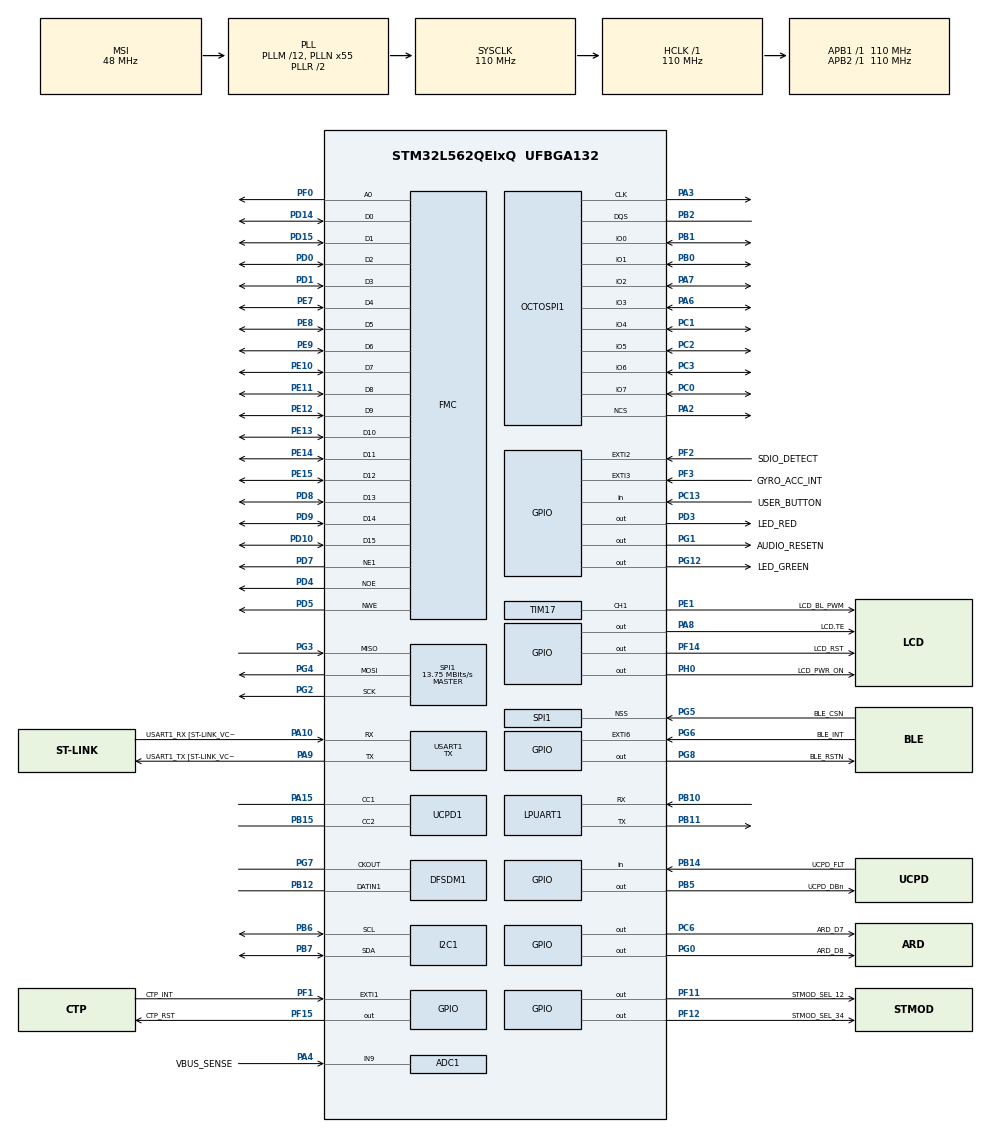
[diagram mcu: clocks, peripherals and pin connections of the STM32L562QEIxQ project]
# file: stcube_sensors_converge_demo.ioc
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ADC1.Channel-0\#ChannelRegularConversion=ADC_CHANNEL_9
ADC1.ClockPrescaler=ADC_CLOCK_ASYNC_DIV12
ADC1.NbrOfConversionFlag=1
ADC1.OffsetNumber-0\#ChannelRegularConversion=ADC_OFFSET_NONE
ADC1.Rank-0\#ChannelRegularConversion=1
ADC1.SamplingTime-0\#ChannelRegularConversion=ADC_SAMPLETIME_2CYCLES_5
ADC1.master=1
FREERTOS.Queues01=queue_serial,16,serial_task_request_t,0,Dynamic,NULL,NULL;queue_i2c_request,16,i2c_bus_task_request_t,0,Dynamic,NULL,NULL;queue_sample_logging_request,16,sample_logging_task_request_t,0,Dynamic,NULL,NULL
FREERTOS.Tasks01=idle,8,1024,StartIdleTask,Default,NULL,Dynamic,NULL,NULL;serial,9,1024,StartSerialTask,Default,NULL,Dynamic,NULL,NULL;i2c_bus,11,1024,StartI2cBusTask,Default,NULL,Dynamic,NULL,NULL;button,11,512,StartButtonTask,Default,NULL,Dynamic,NULL,NULL;display,12,1024,StartDisplayTask,Default,NULL,Dynamic,NULL,NULL;motion,12,1024,StartMotionTask,Default,NULL,Dynamic,NULL,NULL;adc,12,1024,StartAdcTask,Default,NULL,Dynamic,NULL,NULL;sample_logging,10,1024,StartSampleLoggingTask,Default,NULL,Dynamic,NULL,NULL
FREERTOS.configENABLE_FPU=1
FREERTOS.configTOTAL_HEAP_SIZE=40000
FREERTOS.configUSE_NEWLIB_REENTRANT=1
I2C1.Timing=0x40505681
Mcu.Family=STM32L5
Mcu.Name=STM32L562QEIxQ
Mcu.Package=UFBGA132
Mcu.TrustZone=disable
NVIC.ADC1_2_IRQn=true\:5\:0\:false\:false\:true\:true\:true\:true
NVIC.I2C1_ER_IRQn=true\:5\:0\:false\:false\:true\:true\:true\:true
NVIC.I2C1_EV_IRQn=true\:5\:0\:false\:false\:true\:true\:true\:true
NVIC.PriorityGroup=NVIC_PRIORITYGROUP_3
NVIC.TIM15_IRQn=true\:0\:0\:true\:false\:true\:false\:false\:true
NVIC.TimeBase=TIM15_IRQn
NVIC.TimeBaseIP=TIM15
NVIC.USART1_IRQn=true\:5\:0\:false\:false\:true\:true\:true\:true
PA10.GPIO_Label=USART1_RX [ST-LINK_VCP_TX]
PA10.Mode=Asynchronous
PA10.Signal=USART1_RX
PA11.Signal=USB_DM
PA12.Signal=USB_DP
PA13\ (JTMS/SWDIO).Mode=Trace_Asynchronous_SW
PA13\ (JTMS/SWDIO).Signal=DEBUG_JTMS-SWDIO
PA14\ (JTCK/SWCLK).Mode=Trace_Asynchronous_SW
PA14\ (JTCK/SWCLK).Signal=DEBUG_JTCK-SWCLK
PA15\ (JTDI).Mode=Source_AllSignals
PA15\ (JTDI).Signal=UCPD1_CC1
PA2.Mode=octods_mode
PA2.Signal=OCTOSPI1_NCS
PA3.Mode=octods_mode
PA3.Signal=OCTOSPI1_CLK
PA4.GPIO_Label=VBUS_SENSE
PA4.Signal=ADCx_IN9
PA6.Mode=octods_mode
PA6.Signal=OCTOSPI1_IO3
PA7.Mode=octods_mode
PA7.Signal=OCTOSPI1_IO2
PA8.GPIO_Label=LCD.TE
PA8.Signal=GPIO_Output
PA9.GPIO_Label=USART1_TX [ST-LINK_VCP_RX]
PA9.Mode=Asynchronous
PA9.Signal=USART1_TX
PB0.Mode=octods_mode
PB0.Signal=OCTOSPI1_IO1
PB1.Mode=octods_mode
PB1.Signal=OCTOSPI1_IO0
PB10.Mode=Asynchronous
PB10.Signal=LPUART1_RX
PB11.Mode=Asynchronous
PB11.Signal=LPUART1_TX
PB12.Signal=S_DATAIN1DFSDM1
PB14.GPIO_Label=UCPD_FLT
PB14.Signal=GPIO_Input
PB15.Mode=Source_AllSignals
PB15.Signal=UCPD1_CC2
PB2.Mode=octods_mode
PB2.Signal=OCTOSPI1_DQS
PB3\ (JTDO/TRACESWO).Mode=Trace_Asynchronous_SW
PB3\ (JTDO/TRACESWO).Signal=DEBUG_JTDO-SWO
PB5.GPIO_Label=UCPD_DBn
PB5.Signal=GPIO_Output
PB6.GPIO_Pu=GPIO_PULLUP
PB6.Mode=I2C
PB6.Signal=I2C1_SCL
PB7.GPIO_Pu=GPIO_PULLUP
PB7.Mode=I2C
PB7.Signal=I2C1_SDA
PC0.Mode=octods_mode
PC0.Signal=OCTOSPI1_IO7
PC1.Mode=octods_mode
PC1.Signal=OCTOSPI1_IO4
PC10.Signal=SDMMC1_D2
PC11.Signal=SDMMC1_D3
PC12.Signal=SDMMC1_CK
PC13.GPIO_Label=USER_BUTTON
PC13.Signal=GPIO_Input
PC14-OSC32_IN\ (PC14).Mode=LSE-External-Oscillator
PC14-OSC32_IN\ (PC14).Signal=RCC_OSC32_IN
PC15-OSC32_OUT\ (PC15).Mode=LSE-External-Oscillator
PC15-OSC32_OUT\ (PC15).Signal=RCC_OSC32_OUT
PC2.Mode=octods_mode
PC2.Signal=OCTOSPI1_IO5
PC3.Mode=octods_mode
PC3.Signal=OCTOSPI1_IO6
PC6.GPIO_Label=ARD_D7
PC6.Signal=GPIO_Output
PC8.Signal=SDMMC1_D0
PC9.Signal=SDMMC1_D1
PD0.Signal=FMC_D2_DA2
PD1.Signal=FMC_D3_DA3
PD10.Signal=FMC_D15_DA15
PD14.Signal=FMC_D0_DA0
PD15.Signal=FMC_D1_DA1
PD2.Signal=SDMMC1_CMD
PD3.GPIO_Label=LED_RED
PD3.PinState=GPIO_PIN_SET
PD3.Signal=GPIO_Output
PD4.Signal=FMC_NOE
PD5.Signal=FMC_NWE
PD7.Mode=NorPsramChipSelect1_1
PD7.Signal=FMC_NE1
PD8.Signal=FMC_D13_DA13
PD9.Signal=FMC_D14_DA14
PE1.GPIO_Label=LCD_BL_PWM
PE1.Signal=S_TIM17_CH1
PE10.Signal=FMC_D7_DA7
PE11.Signal=FMC_D8_DA8
PE12.Signal=FMC_D9_DA9
PE13.Signal=FMC_D10_DA10
PE14.Signal=FMC_D11_DA11
PE15.Signal=FMC_D12_DA12
PE2.Signal=SAI1_MCLK_A
PE3.Signal=SAI1_SD_B
PE4.Signal=SAI1_FS_A
PE5.Signal=SAI1_SCK_A
PE6.Signal=SAI1_SD_A
PE7.Signal=FMC_D4_DA4
PE8.Signal=FMC_D5_DA5
PE9.Signal=FMC_D6_DA6
PF0.Signal=FMC_A0
PF1.GPIO_Label=CTP_INT
PF1.Signal=GPXTI1
PF11.GPIO_Label=STMOD_SEL_12
PF11.Signal=GPIO_Output
PF12.GPIO_Label=STMOD_SEL_34
PF12.Signal=GPIO_Output
PF14.GPIO_Label=LCD_RST
PF14.Signal=GPIO_Output
PF15.GPIO_Label=CTP_RST
PF15.Signal=GPIO_Output
PF2.GPIO_Label=SDIO_DETECT
PF2.Signal=GPXTI2
PF3.GPIO_Label=GYRO_ACC_INT
PF3.Signal=GPXTI3
PG0.GPIO_Label=ARD_D8
PG0.Signal=GPIO_Output
PG1.GPIO_Label=AUDIO_RESETN
PG1.Signal=GPIO_Output
PG12.GPIO_Label=LED_GREEN
PG12.Signal=GPIO_Output
PG2.Mode=Full_Duplex_Master
PG2.Signal=SPI1_SCK
PG3.Mode=Full_Duplex_Master
PG3.Signal=SPI1_MISO
PG4.Mode=Full_Duplex_Master
PG4.Signal=SPI1_MOSI
PG5.GPIO_Label=BLE_CSN
PG5.Mode=NSS_Signal_Hard_Input
PG5.Signal=SPI1_NSS
PG6.GPIO_Label=BLE_INT
PG6.Signal=GPXTI6
PG7.Signal=S_CKOUTDFSDM1
PG8.GPIO_Label=BLE_RSTN
PG8.Signal=GPIO_Output
PH0-OSC_IN\ (PH0).GPIO_Label=LCD_PWR_ON
PH0-OSC_IN\ (PH0).GPIO_ModeDefaultOutputPP=GPIO_MODE_OUTPUT_PP
PH0-OSC_IN\ (PH0).PinState=GPIO_PIN_RESET
PH0-OSC_IN\ (PH0).Signal=GPIO_Output
ProjectManager.HeapSize=0x200
ProjectManager.StackSize=0x400
ProjectManager.TargetToolchain=STM32CubeIDE
RCC.ADCFreq_Value=96000000
RCC.AHBFreq_Value=110000000
RCC.APB1Freq_Value=110000000
RCC.APB1TimFreq_Value=110000000
RCC.APB2Freq_Value=110000000
RCC.APB2TimFreq_Value=110000000
RCC.CK48CLockSelection=RCC_USBCLKSOURCE_MSI
RCC.CortexFreq_Value=110000000
RCC.HCLKFreq_Value=110000000
RCC.HSE_VALUE=8000000
RCC.HSI48_VALUE=48000000
RCC.HSI_VALUE=16000000
RCC.MSIClockRange=RCC_MSIRANGE_11
RCC.MSI_VALUE=48000000
RCC.PLLM=12
RCC.PLLN=55
RCC.PLLSAI1M=4
RCC.PLLSAI1N=48
RCC.PLLSAI1P=RCC_PLLP_DIV17
RCC.PLLSAI1Source=RCC_PLLSAI1SOURCE_HSI
RCC.SDMMCClockSelection=RCC_SDIOCLKSOURCE_CLK48
RCC.SYSCLKFreq_VALUE=110000000
RCC.SYSCLKSource=RCC_SYSCLKSOURCE_PLLCLK
RCC.USBFreq_Value=48000000
RCC.VCOOutputFreq_Value=220000000
SH.ADCx_IN9.0=ADC1_IN9,IN9-Single-Ended
SH.FMC_A0.0=FMC_A0,A0_1
SH.FMC_D0_DA0.0=FMC_DA0
SH.FMC_D0_DA0.1=FMC_D0,16b-d1
SH.FMC_D10_DA10.0=FMC_DA10
SH.FMC_D10_DA10.1=FMC_D10,16b-d1
SH.FMC_D11_DA11.0=FMC_DA11
SH.FMC_D11_DA11.1=FMC_D11,16b-d1
SH.FMC_D12_DA12.0=FMC_DA12
SH.FMC_D12_DA12.1=FMC_D12,16b-d1
SH.FMC_D13_DA13.0=FMC_DA13
SH.FMC_D13_DA13.1=FMC_D13,16b-d1
SH.FMC_D14_DA14.0=FMC_DA14
SH.FMC_D14_DA14.1=FMC_D14,16b-d1
SH.FMC_D15_DA15.0=FMC_DA15
SH.FMC_D15_DA15.1=FMC_D15,16b-d1
SH.FMC_D1_DA1.0=FMC_DA1
SH.FMC_D1_DA1.1=FMC_D1,16b-d1
SH.FMC_D2_DA2.0=FMC_DA2
SH.FMC_D2_DA2.1=FMC_D2,16b-d1
SH.FMC_D3_DA3.0=FMC_DA3
SH.FMC_D3_DA3.1=FMC_D3,16b-d1
SH.FMC_D4_DA4.0=FMC_DA4
SH.FMC_D4_DA4.1=FMC_D4,16b-d1
SH.FMC_D5_DA5.0=FMC_DA5
SH.FMC_D5_DA5.1=FMC_D5,16b-d1
SH.FMC_D6_DA6.0=FMC_DA6
SH.FMC_D6_DA6.1=FMC_D6,16b-d1
SH.FMC_D7_DA7.0=FMC_DA7
SH.FMC_D7_DA7.1=FMC_D7,16b-d1
SH.FMC_D8_DA8.0=FMC_DA8
SH.FMC_D8_DA8.1=FMC_D8,16b-d1
SH.FMC_D9_DA9.0=FMC_DA9
SH.FMC_D9_DA9.1=FMC_D9,16b-d1
SH.FMC_NOE.0=FMC_NOE,Lcd1
SH.FMC_NWE.0=FMC_NWE,Lcd1
SH.S_CKOUTDFSDM1.0=DFSDM1_CKOUT,CKOUT
SH.S_DATAIN1DFSDM1.0=DFSDM1_DATIN1,Manchester_input_from_ch1
SH.S_TIM17_CH1.0=TIM17_CH1,PWM Generation1 CH1
SPI1.BaudRatePrescaler=SPI_BAUDRATEPRESCALER_8
SPI1.CalculateBaudRate=13.75 MBits/s
SPI1.Direction=SPI_DIRECTION_2LINES
SPI1.Mode=SPI_MODE_MASTER
SPI1.VirtualNSS=VM_NSSHARD
SPI1.VirtualType=VM_MASTER
TIM17.Channel=TIM_CHANNEL_1
USART1.DMADisableonRxErrorParam=ADVFEATURE_DMA_DISABLEONRXERROR
USART1.FIFOMode=FIFOMODE_ENABLE
USART1.Mode=MODE_TX
USART1.OverrunDisableParam=ADVFEATURE_OVERRUN_DISABLE
USART1.RxPinLevelInvertParam=ADVFEATURE_RXINV_DISABLE
USART1.TXFIFOThreshold=TXFIFO_THRESHOLD_1EIGHTHFULL
USART1.VirtualMode-Asynchronous=VM_ASYNC
VP_ADC1_TempSens_Input.Mode=IN-TempSens
VP_DFSDM1_VS_IN0.Mode=Parallel_Input_ch0
VP_DFSDM1_VS_IN2.Mode=Parallel_Input_ch2
VP_FREERTOS_VS_CMSIS_V2.Mode=CMSIS_V2
VP_PWR_VS_DBSignals.Mode=DisableDeadBatterySignals
VP_PWR_VS_SECSignals.Mode=Security/Privilege
VP_SYS_VS_tim15.Mode=TIM15
VP_TIM16_VS_ClockSourceINT.Mode=Enable_Timer
VP_TIM17_VS_ClockSourceINT.Mode=Enable_Timer
VP_TIM4_VS_ClockSourceITR.Mode=TriggerSource_ITR1
VP_TIM4_VS_ControllerModeClock.Mode=Clock Mode
board=STM32L562E-DK

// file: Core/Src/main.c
/* USER CODE BEGIN Header */
/**
  ******************************************************************************
  * @file           : main.c
  * @brief          : Main program body
  ******************************************************************************
  * @attention
  *
  * <h2><center>&copy; Copyright (c) 2021 STMicroelectronics.
  * All rights reserved.</center></h2>
  *
  * This software component is licensed by ST under BSD 3-Clause license,
  * the "License"; You may not use this file except in compliance with the
  * License. You may obtain a copy of the License at:
  *                        opensource.org/licenses/BSD-3-Clause
  *
  ******************************************************************************
  */
/* USER CODE END Header */
#include "main.h"
#include "cmsis_os.h"
#include "adc.h"
#include "dfsdm.h"
#include "i2c.h"
#include "usart.h"
#include "octospi.h"
#include "spi.h"
#include "tim.h"
#include "ucpd.h"
#include "gpio.h"
#include "fmc.h"

/* USER CODE BEGIN Includes */

#include "application.h"

/* USER CODE END Includes */

void SystemClock_Config(void);
void MX_FREERTOS_Init(void);

int main(void)
{
  /* USER CODE BEGIN 1 */

  application_on_reset();

  /* USER CODE END 1 */

  /* MCU Configuration--------------------------------------------------------*/

  /* Reset of all peripherals, Initializes the Flash interface and the Systick. */
  HAL_Init();

  /* Configure the system clock */
  SystemClock_Config();

  /* Initialize all configured peripherals */
  MX_GPIO_Init();
  MX_ADC1_Init();
  MX_DFSDM1_Init();
  MX_FMC_Init();
  MX_I2C1_Init();
  MX_LPUART1_UART_Init();
  MX_USART1_UART_Init();
  MX_OCTOSPI1_Init();
  MX_SPI1_Init();
  MX_TIM4_Init();
  MX_TIM16_Init();
  MX_TIM17_Init();
  MX_UCPD1_Init();
  /* USER CODE BEGIN 2 */

  application_init();

  __enable_irq();
  /* USER CODE END 2 */

  /* Init scheduler */
  osKernelInitialize();  /* Call init function for freertos objects (in freertos.c) */
  MX_FREERTOS_Init();
  /* Start scheduler */
  osKernelStart();

  /* We should never get here as control is now taken by the scheduler */
  /* Infinite loop */
  __disable_irq();
  while (1)
  {

    /* USER CODE BEGIN 3 */
    HAL_GPIO_WritePin(LED_RED_GPIO_Port, LED_RED_Pin, GPIO_PIN_RESET);

    application_end_of_main();
  }
  /* USER CODE END 3 */
}

void SystemClock_Config(void)
{
  RCC_OscInitTypeDef RCC_OscInitStruct = {0};
  RCC_ClkInitTypeDef RCC_ClkInitStruct = {0};

  /** Configure the main internal regulator output voltage
  */
  if (HAL_PWREx_ControlVoltageScaling(PWR_REGULATOR_VOLTAGE_SCALE0) != HAL_OK)
  {
    Error_Handler();
  }
  /** Initializes the RCC Oscillators according to the specified parameters
  * in the RCC_OscInitTypeDef structure.
  */
  RCC_OscInitStruct.OscillatorType = RCC_OSCILLATORTYPE_HSI|RCC_OSCILLATORTYPE_MSI;
  RCC_OscInitStruct.HSIState = RCC_HSI_ON;
  RCC_OscInitStruct.HSICalibrationValue = RCC_HSICALIBRATION_DEFAULT;
  RCC_OscInitStruct.MSIState = RCC_MSI_ON;
  RCC_OscInitStruct.MSICalibrationValue = RCC_MSICALIBRATION_DEFAULT;
  RCC_OscInitStruct.MSIClockRange = RCC_MSIRANGE_11;
  RCC_OscInitStruct.PLL.PLLState = RCC_PLL_ON;
  RCC_OscInitStruct.PLL.PLLSource = RCC_PLLSOURCE_MSI;
  RCC_OscInitStruct.PLL.PLLM = 12;
  RCC_OscInitStruct.PLL.PLLN = 55;
  RCC_OscInitStruct.PLL.PLLP = RCC_PLLP_DIV7;
  RCC_OscInitStruct.PLL.PLLQ = RCC_PLLQ_DIV2;
  RCC_OscInitStruct.PLL.PLLR = RCC_PLLR_DIV2;
  if (HAL_RCC_OscConfig(&RCC_OscInitStruct) != HAL_OK)
  {
    Error_Handler();
  }
  /** Initializes the CPU, AHB and APB buses clocks
  */
  RCC_ClkInitStruct.ClockType = RCC_CLOCKTYPE_HCLK|RCC_CLOCKTYPE_SYSCLK
                              |RCC_CLOCKTYPE_PCLK1|RCC_CLOCKTYPE_PCLK2;
  RCC_ClkInitStruct.SYSCLKSource = RCC_SYSCLKSOURCE_PLLCLK;
  RCC_ClkInitStruct.AHBCLKDivider = RCC_SYSCLK_DIV1;
  RCC_ClkInitStruct.APB1CLKDivider = RCC_HCLK_DIV1;
  RCC_ClkInitStruct.APB2CLKDivider = RCC_HCLK_DIV1;

  if (HAL_RCC_ClockConfig(&RCC_ClkInitStruct, FLASH_LATENCY_5) != HAL_OK)
  {
    Error_Handler();
  }
}

void HAL_TIM_PeriodElapsedCallback(TIM_HandleTypeDef *htim)
{
  if (htim->Instance == TIM15) {
    HAL_IncTick();
  }
}

void Error_Handler(void)
{
  /* USER CODE BEGIN Error_Handler_Debug */
  __disable_irq();
  while (1)
  {
    HAL_GPIO_WritePin(LED_RED_GPIO_Port, LED_RED_Pin, GPIO_PIN_RESET);
  }
  /* USER CODE END Error_Handler_Debug */
}

#ifdef  USE_FULL_ASSERT
/**
  * @brief  Reports the name of the source file and the source line number
  *         where the assert_param error has occurred.
  * @param  file: pointer to the source file name
  * @param  line: assert_param error line source number
  * @retval None
  */
void assert_failed(uint8_t *file, uint32_t line)
{
  /* USER CODE BEGIN 6 */
  __disable_irq();
  while (1)
  {
    HAL_GPIO_WritePin(LED_RED_GPIO_Port, LED_RED_Pin, GPIO_PIN_RESET);
  }
  /* USER CODE END 6 */
}
#endif /* USE_FULL_ASSERT */

/************************ (C) COPYRIGHT STMicroelectronics *****END OF FILE****/

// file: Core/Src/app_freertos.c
/* USER CODE BEGIN Header */
/**
  ******************************************************************************
  * File Name          : app_freertos.c
  * Description        : Code for freertos applications
  ******************************************************************************
  * @attention
  *
  * <h2><center>&copy; Copyright (c) 2021 STMicroelectronics.
  * All rights reserved.</center></h2>
  *
  * This software component is licensed by ST under Ultimate Liberty license
  * SLA0044, the "License"; You may not use this file except in compliance with
  * the License. You may obtain a copy of the License at:
  *                             www.st.com/SLA0044
  *
  ******************************************************************************
  */
/* USER CODE END Header */

#include "FreeRTOS.h"
#include "task.h"
#include "main.h"
#include "cmsis_os.h"

/* USER CODE BEGIN Includes */

#include "application.h"
#include "i2c_bus_task.h"
#include "serial_task.h"
#include "sample_logging_task.h"

/* USER CODE END Includes */

/* Definitions for idle */
osThreadId_t idleHandle;
const osThreadAttr_t idle_attributes = {
  .name = "idle",
  .priority = (osPriority_t) osPriorityLow,
  .stack_size = 1024 * 4
};
/* Definitions for serial */
osThreadId_t serialHandle;
const osThreadAttr_t serial_attributes = {
  .name = "serial",
  .priority = (osPriority_t) osPriorityLow1,
  .stack_size = 1024 * 4
};
/* Definitions for i2c_bus */
osThreadId_t i2c_busHandle;
const osThreadAttr_t i2c_bus_attributes = {
  .name = "i2c_bus",
  .priority = (osPriority_t) osPriorityLow3,
  .stack_size = 1024 * 4
};
/* Definitions for button */
osThreadId_t buttonHandle;
const osThreadAttr_t button_attributes = {
  .name = "button",
  .priority = (osPriority_t) osPriorityLow3,
  .stack_size = 512 * 4
};
/* Definitions for display */
osThreadId_t displayHandle;
const osThreadAttr_t display_attributes = {
  .name = "display",
  .priority = (osPriority_t) osPriorityLow4,
  .stack_size = 1024 * 4
};
/* Definitions for motion */
osThreadId_t motionHandle;
const osThreadAttr_t motion_attributes = {
  .name = "motion",
  .priority = (osPriority_t) osPriorityLow4,
  .stack_size = 1024 * 4
};
/* Definitions for adc */
osThreadId_t adcHandle;
const osThreadAttr_t adc_attributes = {
  .name = "adc",
  .priority = (osPriority_t) osPriorityLow4,
  .stack_size = 1024 * 4
};
/* Definitions for sample_logging */
osThreadId_t sample_loggingHandle;
const osThreadAttr_t sample_logging_attributes = {
  .name = "sample_logging",
  .priority = (osPriority_t) osPriorityLow2,
  .stack_size = 1024 * 4
};
/* Definitions for queue_serial */
osMessageQueueId_t queue_serialHandle;
const osMessageQueueAttr_t queue_serial_attributes = {
  .name = "queue_serial"
};
/* Definitions for queue_i2c_request */
osMessageQueueId_t queue_i2c_requestHandle;
const osMessageQueueAttr_t queue_i2c_request_attributes = {
  .name = "queue_i2c_request"
};
/* Definitions for queue_sample_logging_request */
osMessageQueueId_t queue_sample_logging_requestHandle;
const osMessageQueueAttr_t queue_sample_logging_request_attributes = {
  .name = "queue_sample_logging_request"
};

void StartIdleTask(void *argument);
void StartSerialTask(void *argument);
void StartI2cBusTask(void *argument);
void StartButtonTask(void *argument);
void StartDisplayTask(void *argument);
void StartMotionTask(void *argument);
void StartAdcTask(void *argument);
void StartSampleLoggingTask(void *argument);

void MX_FREERTOS_Init(void); /* (MISRA C 2004 rule 8.1) */

void MX_FREERTOS_Init(void) {

  /* Create the queue(s) */
  /* creation of queue_serial */
  queue_serialHandle = osMessageQueueNew (16, sizeof(serial_task_request_t), &queue_serial_attributes);

  /* creation of queue_i2c_request */
  queue_i2c_requestHandle = osMessageQueueNew (16, sizeof(i2c_bus_task_request_t), &queue_i2c_request_attributes);

  /* creation of queue_sample_logging_request */
  queue_sample_logging_requestHandle = osMessageQueueNew (16, sizeof(sample_logging_task_request_t), &queue_sample_logging_request_attributes);

  /* Create the thread(s) */
  /* creation of idle */
  idleHandle = osThreadNew(StartIdleTask, NULL, &idle_attributes);

  /* creation of serial */
  serialHandle = osThreadNew(StartSerialTask, NULL, &serial_attributes);

  /* creation of i2c_bus */
  i2c_busHandle = osThreadNew(StartI2cBusTask, NULL, &i2c_bus_attributes);

  /* creation of button */
  buttonHandle = osThreadNew(StartButtonTask, NULL, &button_attributes);

  /* creation of display */
  displayHandle = osThreadNew(StartDisplayTask, NULL, &display_attributes);

  /* creation of motion */
  motionHandle = osThreadNew(StartMotionTask, NULL, &motion_attributes);

  /* creation of adc */
  adcHandle = osThreadNew(StartAdcTask, NULL, &adc_attributes);

  /* creation of sample_logging */
  sample_loggingHandle = osThreadNew(StartSampleLoggingTask, NULL, &sample_logging_attributes);

}

void StartIdleTask(void *argument)
{
  /* USER CODE BEGIN StartIdleTask */

  application_start_task_idle(idleHandle);

  /* USER CODE END StartIdleTask */
}

void StartSerialTask(void *argument)
{
  /* USER CODE BEGIN StartSerialTask */

  application_start_task_serial(serialHandle, queue_serialHandle);

  /* USER CODE END StartSerialTask */
}

void StartI2cBusTask(void *argument)
{
  /* USER CODE BEGIN StartI2cBusTask */

  application_start_task_i2c_bus(i2c_busHandle, queue_i2c_requestHandle);

  /* USER CODE END StartI2cBusTask */
}

void StartButtonTask(void *argument)
{
  /* USER CODE BEGIN StartButtonTask */

  application_start_task_button(buttonHandle);

  /* USER CODE END StartButtonTask */
}

void StartDisplayTask(void *argument)
{
  /* USER CODE BEGIN StartDisplayTask */

  application_start_task_display(displayHandle);

  /* USER CODE END StartDisplayTask */
}

void StartMotionTask(void *argument)
{
  /* USER CODE BEGIN StartMotionTask */

  application_start_task_motion(motionHandle);

  /* USER CODE END StartMotionTask */
}

void StartAdcTask(void *argument)
{
  /* USER CODE BEGIN StartAdcTask */

  application_start_task_adc(adcHandle);

  /* USER CODE END StartAdcTask */
}

void StartSampleLoggingTask(void *argument)
{
  /* USER CODE BEGIN StartSampleLoggingTask */

  application_start_task_sample_logging(sample_loggingHandle, queue_sample_logging_requestHandle);

  /* USER CODE END StartSampleLoggingTask */
}

/************************ (C) COPYRIGHT STMicroelectronics *****END OF FILE****/
